# debugss_DEBUGSS_TBR_VBUSP_WRAP_TBR_CFG_TBR_CFG_00073C025000h register map
Vendor: Texas Instruments
Peripheral module from a debugger description file (folder AM275x).
Registers are 32-bit, read-only, reset 0x0 unless marked. A register's access mark holds for its fields unless they carry their own. Offsets are as the file gives them; lines under a group give offsets from that group; [hi:lo] are bit positions; {n}, {i} and the like mark numbered series; 'fields as' and 'values as' point back to an identical list; <NAME> marks a mode.

## debugss_TBR_VBUSP_WRAP_TBR_CFG_TBR_CFG
0x04 DEBUGSS_TBR_VBUSP_WRAP_TBR_CFG_TBR_CFG_CT_TBR_RAMSZ — CT-TBR RAM Size Register This register indicates the size of the local memory buffer interfaced with the CT-TBR This register can be used to determine if the CT_TBR is synthesized for System Bridge Mode only. It will read 0x00000000 in this configuration.
  [2:0] RAM_SIZE — Indicates the size of the local memory1 Read 0x0 : No local buffer. TBR Bridge only configuration Read 0x1 : 4K bytes Read 0x2 : 8K bytes Read 0x3 : 16K bytes Read 0x4 : 32K bytes Read 0x5 : 64K bytes Read 0x6 : 128K bytes Read 0x7 : Reserved
0x08 DEBUGSS_TBR_VBUSP_WRAP_TBR_CFG_TBR_CFG_FIFOSZ — CT-TBR Output FIFO Size Register This register indicates the size of output FIFO used to transfer data to the system target interface
  [2:0] FIFO_SIZE — Indicates the size of the output FIFO Read 0x0 : 128 bytes Read 0x1 : 256 bytes Read 0x2 : 512 bytes Read 0x3 : 1024 bytes Read 0x4 : 2048 bytes Read 0x5-0x7 : Reserved
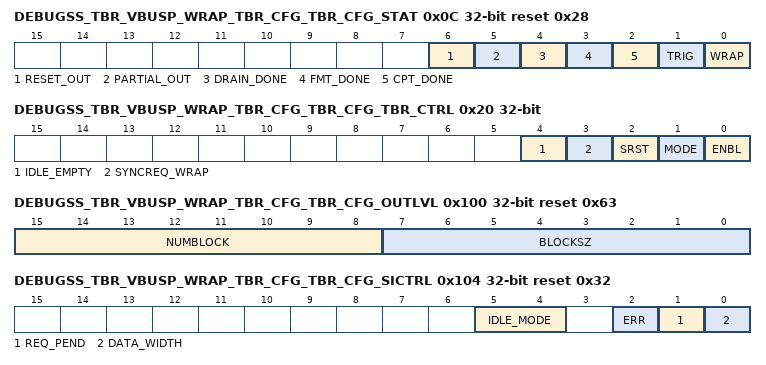
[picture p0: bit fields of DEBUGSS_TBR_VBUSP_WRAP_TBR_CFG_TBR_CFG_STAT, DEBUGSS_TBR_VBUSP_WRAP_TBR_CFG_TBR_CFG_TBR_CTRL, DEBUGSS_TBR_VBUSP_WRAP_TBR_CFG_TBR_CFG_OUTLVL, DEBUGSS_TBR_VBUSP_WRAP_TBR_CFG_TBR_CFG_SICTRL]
0x0C DEBUGSS_TBR_VBUSP_WRAP_TBR_CFG_TBR_CFG_STAT reset 0x28 — TBR Status Register This register indicates status of various functions performed by CT-TBR
  [6] RESET_OUT — Reset Active bit indicates that at least one of the domains in the CT-TBR is currently being held in reset. Read 0b : All domains and/or interfaces of the CT-TBR are out of reset Read 1b : At least one of the domains and/or interfaces of the CT-TBR are being held in reset
  [5] PARTIAL_OUT — Indicates that a partial output block (0 < Level < Trigger Threshold) is in the TBR memory (output buffer and possibly local RAM) and that an OUTFLUSH sequence may be required since there is no valid data to available to increase the amount of data past the OUTLVL threshold (i.e. local RAM buffer is empty). This bit is not set if the partial output block is the result of currently active block read request (i.e. it is already actively draining). This bit is only valid in System Bridge Mode. Read 0b : A partial frame does not exist or there is pending data in the local data RAMs that might complete any partial output blocks. Read 1b : A partial output block is in the buffer and there is not valid data available to push this through the system without an OUTFLUSH. Enabling acquisition (CTRL : ENBL 0- > 1) resets the output FIFO pointers and RAM pointers, so this bit will be set to 0 each time acquisition is enabled.
  [4] DRAIN_DONE — Indicates the whether there is data in the output FIFO. This bit is only valid in System Bridge Mode. Read 0b : There is still valid data in the CT-TBR output FIFO Read 1b : All valid data in the CT-TBR output FIFO has been transferred via the system interface. Enabling acquisition (CTRL : ENBL 0- > 1) resets the output FIFO pointers, so this bit will be set to 0 each time acquisition is enabled.
  [3] FMT_DONE — Indicates that all pending local memory transactions from the formatter are complete and no more data will be posted from the formatter. Read 0b : Data may still be pending Read 1b : Final data from the formatter has been posted. This bit is reset to 0b when the CTRL : ENBL transitions from 0b to 1b.
  [2] CPT_DONE — Indicates that ATB interface is disabled and trace data capture is complete. Read 0b : Trace capture still active Read 1b : Trace capture complete This bit is reset to 0b when the CTRL : ENBL transitions from 0b to 1b.
  [1] TRIG — Indicates that the local memory buffer has been locked as the result of a trigger. This bit is only valid in Buffer Mode and will always read 0 in System Bridge mode Read 0b : No trigger seen. Read 1b : Trigger input detected and buffer locked This bit is reset to 0b when the CTRL : ENBL transitions from 0b to 1b.
  [0] WRAP — This bit is active in buffer mode only and is not present in CT-TBR configurations that only support System bridge mode Indicates that the local memory write pointer has incremented past the upper boundary of the memory reset to the lowest address (at least once). Read 0b : No wrap Read 1b : Write pointer has wrapped This bit is reset to 0b when the CTRL : ENBL transitions from 0b to 1b
0x10 DEBUGSS_TBR_VBUSP_WRAP_TBR_CFG_TBR_CFG_RAMRDAT — RAM Read Data Register This register is used to transfer data from the local memory to client This register is not present when CT-TBR is synthesized for System Bridge Mode only.
  [31:0] DATA — The 32-bit data value pointed to by the RAMRPTR register Reading returns the value at the index specified by RAMRPTR. RAMRPTR is then incremented automatically.
0x14 DEBUGSS_TBR_VBUSP_WRAP_TBR_CFG_TBR_CFG_RAMRPTR rw — RAM Read Pointer Register Indexes into the local memory for reading 32-bit values via RAMRDAT This register is not present when CT-TBR is synthesized for System Bridge Mode only.
  [21:0] PTR — This field designates the index of the 32-bit RAM location to be read via RAMRDAT. Read returns the current value of the pointer Write sets the value and initiates a read from the designated address. This field increments automatically when a value is read from RAMRDAT. This register should not be used when the data acquisition is enabled (results are undefined). The actual width of the pointer field will be determined by the buffer size1
0x18 DEBUGSS_TBR_VBUSP_WRAP_TBR_CFG_TBR_CFG_RAMWPTR rw — This field designates the index of the 32-bit RAM location to be written via RAMWDAT. Read : Returns the current value of the pointer Write : Sets the value Writes will always force the bits 1 : 0 of write_value to 0. This register should not be used when the data acquisition is enabled (results are undefined). The actual width of the pointer field will be determined by the buffer size1
  fields as DEBUGSS_TBR_VBUSP_WRAP_TBR_CFG_TBR_CFG_RAMRPTR
0x1C DEBUGSS_TBR_VBUSP_WRAP_TBR_CFG_TBR_CFG_TRGCNT rw — Trigger Count Register This register controls the amount of data written to the local memory after a trigger input is detected
  [12:0] COUNT — Controls the number of 128-bit words written to local memory after a trigger input is detected on the CTI interface. When the input trigger is active and a trigger is detected, an internal register starts counting the number of 128-bit words written to local memory. When that counter equals COUNT + 1, the memory is locked and the CAPT_DONE and the TRIG bits in the STAT register are set. - Setting COUNT to a low index will lock trace that occurred before the trigger - Setting COUNT to a high index will lock trace that occurred after the trigger - Setting COUNT to an intermediate index will lock trace that occurred around the trigger Read : Returns the current configured value of the trigger counter Write : Sets a new value. This register can be read at any time but can only be written when acquisition is disabled in CNTL. The internal count register is not visible to the application, but it is reset cleared by hardware when the CTRL'ENBL bit transitions from 0 to 1. The width of the COUNT field is actually log2(RAM size in Bytes / 16) When configured for System Bridge only, the COUNT field is fixed a 10-bits (9 : 0). This allows the CT-TBR to capture and forward up to 1024 frames of data after the trigger event.
0x20 DEBUGSS_TBR_VBUSP_WRAP_TBR_CFG_TBR_CFG_TBR_CTRL rw — CT-TBR Control Register This register controls the global enable/disable functions of the CT-TBR
  [4] IDLE_EMPTY — Controls whether the CT_TBR can enter idle with data present Read 0x0 : All internal buffers must be empty before idle requests are acknowledged Read 0x1 : CT_TBR can idle with valid data Write 0x0 : Clear idle with valid data Write 0x1 : Set idle with valid data
  [3] SYNCREQ_WRAP — Controls whether the CT-TBR will issue a pulse on SYNREQ each time the local buffer write pointer wraps back to address 0. Read 0x0 : SYNCREQ generation is suppressed Read 0x1 : SYNCREQ on buffer wrap is enabled Write 0x0 : Disable SYNCREQ generation Write 0x1 : Enable SYNCREQ generation
  [2] SRST — Software initiated reset control Read 0x0 : Always Write 0x0 : No action Write 0x1 : Initiates a software reset
  [1] MODE — This field is the top-level control for determining the operating mode of the module Read 0x0 : Module is in Buffer Mode Read 0x1 : Module is in System Bridge Mode Write 0x0 : Set Buffer Mode Write 0x1 : Set System Bridge Mode This bit can only be written when the ENBL bit is '0' Setting it when acquisition in enabled may result in undefined behavior. This bit is read only and set to '1' when CT-TBR is synthesized for System Bridge only operation.
  [0] ENBL — This field is the top-level control for enabling trace acquisition and processing in the module. Read 0x0 : Module is disabled Read 0x1 : Module is enabled (trace data is being captured and stored to local memory) Write 0x0 : Disable module Write 0x1 : Enable module
0x24 DEBUGSS_TBR_VBUSP_WRAP_TBR_CFG_TBR_CFG_RAMWDAT rw — RAM Write Data Register This register is used to transfer data from the client to local memory This register is not present when CT-TBR is synthesized for System Bridge Mode only.
  [31:0] DATA — The 32-bit data value to be written to local memory Writing initiates the transfer of data to the location pointed at by RAMWPTR. RAMWPTR is then incremented automatically. This register should not be used when the data acquisition is enabled (results are undefined).
0x100 DEBUGSS_TBR_VBUSP_WRAP_TBR_CFG_TBR_CFG_OUTLVL rw reset 0x63 — Output FIFO Trigger Level Register This register controls the size of the data blocks transferred through the output FIFO and across the system interface
  [15:8] NUMBLOCK — Determines blocks (value + 1) that must be sent over the system interface to complete a higher level data frame for transport. This field is used to calculate the total output trigger threshold when used in conjunction with BLOCKSZ field. Output Trigger Threshold (in frames) = (BLOCKSZ + 1) * (NUMBLOCK + 1) The threshold calculations include data in the output FIFO and local RAM buffers (if local RAM exists). Read : Returns the current configured value of the number of blocks in the high level data frame Write : Sets a new value. This register is only valid when the CT-TBR is operating in System Bridge mode This register can be read at any time but can only be written when acquisition is disabled in CNTL. In addition, SW should only update NUMBLOCK when the following conditions are all true : " An output flush sequence is not active (OPCTL : OUTFLUSH == 0) " The system interface output buffer is empty (STAT : DRAIN_DONE == 1)
  [7:0] BLOCKSZ — Determines the block size (the number of 128-bit frames + 1) used by the DMA engine Reading data over the system interface. This field is used to calculate the total output trigger threshold when used in conjunction with NUMBLOCK field. The block size is used by the DMA event logic to determine when to deassert the DMA request. Output Trigger Threshold (in frames) = (BLOCKSZ + 1) * (NUMBLOCK + 1) The threshold calculations include data in the output FIFO and local RAM buffers (if local RAM exists). Read : Returns the current configured value of the block size Write : Sets a new value. The minimum value for BLOCKSZ is 0xF. If configured for less than 0xF, the behavior of the system interface is undefined. This register is only valid when the CT-TBR is operating in System Bridge mode This register can be read at any time but can only be written when acquisition is disabled in CNTL. In addition, SW should only update BLOCKSZ when the following conditions are all true : " An output flush sequence is not active (OPCTL : OUTFLUSH == 0) " The system interface output buffer is empty (STAT : DRAIN_DONE == 1)
0x104 DEBUGSS_TBR_VBUSP_WRAP_TBR_CFG_TBR_CFG_SICTRL access per field reset 0x32 — CT-TBR System Interface Control This register provides control and status for the system interface of the CT-TBR
  [5:4] IDLE_MODE rw — This bit-field controls the idle behavior of the CT-TRB Read : Indicates the Idle modes outlined below Write 00b : Set Force-Idle. For CT-TBR, Force-Idle is identical to Smart-Idle Write 01b : Set No-Idle : The CT_TBR will acknowledge the idle request, but never transition to the idle state Write 10b : Set Smart-Idle : The CT-TBR uses the smart idle protocol. This is the default mode. Write 11b : Set Smart-Idle-Wkup : Since the CT-TBR does not support internal wakeup, this mode is identical to Smart-Idle
  [2] ERR rw — This bit indicates that an access on the System Target I/F resulted in a error Read 0x0 : No errors since last clear Read 0x1 : At least one error condition on the I/F since last clear Write 0x0 : No effect Write 0x1 : Clears bit to 0 This bit clears to 0 when data acquisition is enabled (CTRL : ENBL 0- > 1)
  [1] REQ_PEND ro — This bit indicates if a read request is pending or active on the system interface Read 0x0 : No read requests pending or active Read 0x1 : A system initiator has posted a read request on the system interface and this request is pending or being serviced
  [0] DATA_WIDTH rw — This bit controls the supported access size for the system interface Read 0x0 : System interface will only support 32-bit reads Read 0x1 : System interface will only support 64-bit reads Write 0x0 : Set 32-bit mode Write 0x1 : Set 64-bit mode This bit is RO and set to 0 when synthesized for 32-bit data width
0x108 DEBUGSS_TBR_VBUSP_WRAP_TBR_CFG_TBR_CFG_IDPERIOD rw — ID Repeat Period Register This register controls the number of frames (without and ID change marker) that will be sent before the formatter forces and ID marker
  [9:0] PERIOD — Controls the number of 128-bit frames (with no ID change markers) that the formatter will forward before forcing an artificial ID change. Read : Returns the current configured value of the period Write : Sets the value Setting to 0 disables the forcing of IDs, but this is not recommended. PERIOD should only be updated when trace acquisition is disabled
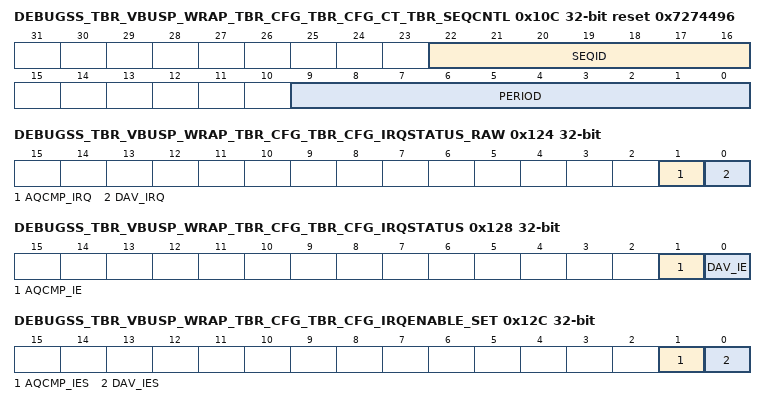
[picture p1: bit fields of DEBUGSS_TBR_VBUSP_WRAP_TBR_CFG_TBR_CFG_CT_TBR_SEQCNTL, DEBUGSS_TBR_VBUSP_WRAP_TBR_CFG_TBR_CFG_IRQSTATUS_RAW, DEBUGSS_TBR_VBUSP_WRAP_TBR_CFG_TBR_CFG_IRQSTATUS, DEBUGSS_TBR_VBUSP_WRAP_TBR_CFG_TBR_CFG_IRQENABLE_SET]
0x10C DEBUGSS_TBR_VBUSP_WRAP_TBR_CFG_TBR_CFG_CT_TBR_SEQCNTL rw reset 0x7274496
  [22:16] SEQID — PERIOD1This defined the ATID used when inserting the incrementing sequence byte. The reset value is the highest free ID supported in the TWP specification, but this can be overwritten by SW if there are system collisions
  [9:0] PERIOD — Controls the number of 128-bit frames that the formatter will forward before inserting an 8-bit incrementing sequence number into a frame using ATID defined in SEQID Read : Returns the current configured value of the period Write : Sets the value Setting to 0 disables the insertion of the incrementing sequence bytes, PERIOD should only be updated when trace acquisition is disabled
0x120 DEBUGSS_TBR_VBUSP_WRAP_TBR_CFG_TBR_CFG_EOI rw — CT-TBR EOI register This register is the End of Interrupt used by SW to signal HW that an interrupt service is complete and an interrupt can be rearmed.
  [0] EOI_VECT — This bit is used by SW to signal that a particular interrupt generated by the IP can be rearmed. Read 0x0 : Always Write 0x0 : DAV_IRQ is rearmed (it is IRQ index 0 for this IP) Write 0x1 : AQCMP_IRQ is rearmed (it is IRQ index 1)
0x124 DEBUGSS_TBR_VBUSP_WRAP_TBR_CFG_TBR_CFG_IRQSTATUS_RAW rw — CT-TBR IRQ Status (Raw) register This register provides control and status for the interrupt/event interface The IRQSTATUS_RAW register may be modified while acquisition is enabled
  [1] AQCMP_IRQ — This bit controls the acquisition complete interrupt/event generation for testing Read 0x0 : Acquisition complete interrupt is not active Read 0x1 : Acquisition complete interrupt is active and awaiting completion. The enabled state is not considered. Write 0x0 : No effect Write 0x1 : Sets the interrupt request for testing
  [0] DAV_IRQ — This bit controls the data available interrupt/event generation for testing Read 0x0 : Data available interrupt is not active Read 0x1 : Data available interrupt is active and awaiting completion. The enabled state is not considered. Write 0x0 : No effect Write 0x1 : Sets the interrupt request for testing
0x128 DEBUGSS_TBR_VBUSP_WRAP_TBR_CFG_TBR_CFG_IRQSTATUS rw — CT-TBR IRQ Status register This register provides control and status for the interrupt/event interface The IRQSTATUS register may be modified while acquisition is enabled
  [1] AQCMP_IE — Acquisition complete interrupt enable Read 0x0 : Acquisition complete interrupt/event generation is either not pending or it is not enabled Read 0x1 : The acquisition complete interrupt is pending and enabled. Write 0x0 : No effect Write 0x1 : Clears a pending Acquisition complete interrupt
  [0] DAV_IE — Data Available interrupt enable Read 0x0 : Data available interrupt/event generation is either not pending or it is disabled Read 0x1 : Data available interrupt is pending and enabled. Write 0x0 : No effect Write 0x1 : Clears a pending data available interrupt
0x12C DEBUGSS_TBR_VBUSP_WRAP_TBR_CFG_TBR_CFG_IRQENABLE_SET rw — CT-TBR IRQ Enable set register This register provides control for the interrupt/event interface The IRQENABLE_SET register may be modified while acquisition is enabled
  [1] AQCMP_IES — Provides enable state and sets the enable of the acquisition complete interrupt/event Read 0x0 : The acquisition complete interrupt is disabled Read 0x1 : The acquisition complete interrupt is enabled Write 0x0 : No effect Write 0x1 : Enables the acquisition complete interrupt/event
  [0] DAV_IES — Provides enable state and sets the enable of the data available interrupt/event Read 0x0 : The data available interrupt is disabled Read 0x1 : The data available interrupt is enabled Write 0x0 : No effect Write 0x1 : Enables the data available interrupt/event
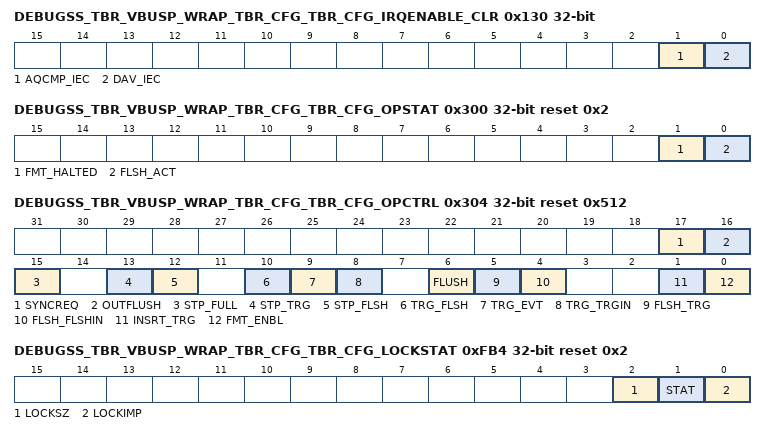
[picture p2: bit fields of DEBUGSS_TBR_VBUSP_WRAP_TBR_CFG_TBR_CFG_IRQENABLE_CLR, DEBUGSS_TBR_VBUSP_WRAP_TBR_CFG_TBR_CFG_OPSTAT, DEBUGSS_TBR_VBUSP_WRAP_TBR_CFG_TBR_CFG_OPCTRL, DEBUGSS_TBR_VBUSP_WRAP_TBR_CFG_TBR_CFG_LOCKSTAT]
0x130 DEBUGSS_TBR_VBUSP_WRAP_TBR_CFG_TBR_CFG_IRQENABLE_CLR rw — CT-TBR IRQ Enable clear register This register provides control for the interrupt/event interface The IRQENABLE_CLR register may be modified while acquisition is enabled
  [1] AQCMP_IEC — Provides enable state and clears the enable of the data available interrupt/event Read 0x0 : The acquisition complete interrupt is disabled Read 0x1 : The acquisition complete interrupt is enabled Write 0x0 : No effect Write 0x1 : Disables the acquisition complete interrupt/event
  [0] DAV_IEC — Provides enable state and clears the enable of the data available interrupt/event Read 0x0 : The data available interrupt is disabled Read 0x1 : The data available interrupt is enabled Write 0x0 : No effect Write 0x1 : Disables the data available interrupt/event
0x300 DEBUGSS_TBR_VBUSP_WRAP_TBR_CFG_TBR_CFG_OPSTAT reset 0x2 — Operation Status Register This register provides information on the status of various operations of the CT-TBR
  [1] FMT_HALTED — This bit indicates that the formatter is halted and the last available data has been written to the local memory. It is functionally equivalent to the FMT_DONE bit in the STAT register. Read 0x0 : Formatter block is active Read 0x1 : Formatter block is disabled This bit is cleared by hardware when the CTRL'ENBL bit transitions from 0 to 1.
  [0] FLSH_ACT — This bit indicates that a flush request is being processed by the CT-TBR Read 0x0 : No flush requests are active Read 0x1 : Flush request is pending completion
0x304 DEBUGSS_TBR_VBUSP_WRAP_TBR_CFG_TBR_CFG_OPCTRL access per field reset 0x512
  [17] SYNCREQ rw — This bit is allows the SW to stimulate a synchronization request to all the upstream trace components. Read 0x0 : This bit always reads as 0 Write 0x0 : Has no effect Write 0x1 : Results in the assertion of the SYNCREQ signal on the ATB target for one ATCLK cycle. SYNCREQ is available in any operating mode. SYNCREQ should only be written while trace acquisition is enabled.
  [16] OUTFLUSH rw — This bit is the flush control. For the output FIFO (System Bridge Mode) it triggers a flush of this buffer and the flush completes when the last OUTLEVEL + 1 sized burst is read on the system Interface. Read 0x0 : No output flush operation is active Read 0x1 : Output flush operation is active Write 0x0 : No meaning Write 0x1 : Initiate an output buffer flush. Automatically clears to 0 when the operation completes OUTFLUSH may be written while trace acquisition is enabled
  [15] STP_FULL rw — This bit controls whether the formatter stops operation when the local memory buffer is full. This 'one-shot' mode prevents the write pointer from wrapping, Read 0x0 : Formatter continues when write pointer wraps back to the lowest address Read 0x1 : Formatter stops operation when the local memory is full Write 0x0 : Disable formatter halt on full Write 0x1 : Enable formatter halt on full This bit is only functional when the CT-TBR is configured for Buffer Mode (CTRL : MODE == 0).
  [13] STP_TRG rw — This bit controls whether the formatter stops operation when a trigger is detected Read 0x0 : Formatter continues when trigger is detected Read 0x1 : Formatter stops operation when trigger is detected Write 0x0 : Disable formatter halt on trigger Write 0x1 : Enable formatter halt on trigger
  [12] STP_FLSH rw — This bit controls whether the formatter stops operation when a flush completes Read 0x0 : Formatter continues after flush completion Read 0x1 : Formatter stops operation when flush completes Write 0x0 : Disable formatter halt on flush completion Write 0x1 : Enable formatter halt on flush completion
  [10] TRG_FLSH rw — This bit controls whether a trigger event is generated when a flush completes Read 0x0 : No trigger event generated when flush is completed. Read 0x1 : Trigger event generated Write 0x0 : Disable trigger event generation Write 0x1 : Enable trigger event generation
  [9] TRG_EVT rw — This bit controls whether the action associated with a trigger is delayed until the trigger counter matches the value in TRGCNT : COUNT + 1. Read 0x0 : No trigger counter delay Read 0x1 : Trigger action delayed until trigger count match Write 0x0 : Disable trigger delay Write 0x1 : Enable trigger delay
  [8] TRG_TRGIN rw — This bit controls whether a trigger event is generated when a rising edge is detected on the TRIGIN input on the CTI interface. Setting this bit also enables trigger event generation when a trigger ID (ATID = 0x7d) is seen on the ATB interface. Read 0x0 : No trigger event generated on TRIGIN assertion. Read 0x1 : Trigger event generated Write 0x0 : Disable trigger event generation Write 0x1 : Enable trigger event generation
  [6] FLUSH rw — This bit is the manual flush control. It triggers a flush from the trace data sources into the CT-TBR Read 0x0 : No manual flush operation is active Read 0x1 : Manual flush operation is active Write 0x0 : No meaning Write 0x1 : Initiate a manual flush. Automatically clears to 0 when the operation completes FLUSH may be written while trace acquisition is enabled
  [5] FLSH_TRG rw — This bit controls whether a flush operation is initiated when a trigger condition is detected by the CT-TBR Read 0x0 : Flush on trigger event is disabled Read 0x1 : Flush on trigger event is enabled Write 0x0 : Disable flush on trigger event Write 0x1 : Enable flush on trigger event
  [4] FLSH_FLSHIN rw — This bit controls whether a flush operation is initiated when a rising edge is detected on the FLUSHIN input signal Read 0x0 : Flush on FLUSHIN is disabled Read 0x1 : Flush on FLUSHIN is enabled Write 0x0 : Disable flush on FLUSHIN Write 0x1 : Enable flush on FLUSHIN
  [1] INSRT_TRG rw — This bit controls whether the TWP trigger sequence is inserted into the TWP frame a trigger condition is encountered Read 0x0 : Trigger insertion is disabled Read 0x1 : Trigger insertion is enabled Write 0x0 : Disable trigger insertion Write 0x1 : Enable trigger insertion
  [0] FMT_ENBL rw — This bit controls whether the ATB input data is formatted into 128-bit TWP frames Read 0x0 : Formatting is disabled Read 0x1 : Formatting is enabled Write 0x0 : Disable formatting Write 0x1 : Enable formatting
0xFA0 DEBUGSS_TBR_VBUSP_WRAP_TBR_CFG_TBR_CFG_CLAIMSET access per field reset 0x1 — The Claim Tag Set Register The register is used to manage handshakes between application and tools SW using the CT-TBR
  [3:0] CTSET rw — This bit sets the Claim Tag Read 0xF : Always. Indicates that claim tag has 4 valid bits Write 0x0 : No effect Write 0x1-F : Bit value of '1' sets the corresponding Claim Tag bit
0xFA4 DEBUGSS_TBR_VBUSP_WRAP_TBR_CFG_TBR_CFG_CLAIMCLR — The Claim Tag Clear Register The register is used to manage handshakes between application and tools SW using the CT-TBR
  [3:0] CTCLR — This bit clears the Claim Tag Read : The current claim tag value Write 0x0 : No effect Write 0x1-F : Bit value of '1' clears the corresponding bit in the Claim Tag
0xFB0 DEBUGSS_TBR_VBUSP_WRAP_TBR_CFG_TBR_CFG_LOCKACC — The Lock Access Register The register is used to enabled application use of the CT-TBR
  [31:0] CODE — This bit-field is used to unlock the CT-TBR for use by the application Write 0xC5ACCE55 : Unlocks the CT-TBR Write any other value : Lock the CT-TBR
0xFB4 DEBUGSS_TBR_VBUSP_WRAP_TBR_CFG_TBR_CFG_LOCKSTAT reset 0x2 — The Lock Status Register The register is used to manage application use of the CT-TBR
  [2] LOCKSZ — This bit-field indicates the size of the lock access bit-field Read 0x0 : indicates the lock access field is 32-bits wide
  [1] STAT — This bit-field indicates the current state of the lock Read 0x0 : indicates the module is not locked from application accesses Read 0x1 : Indicates the module is locked
  [0] LOCKIMP — This bit-field indicates if the module implements a lock access mechanism Read 0x1 : Indicates a lock is present
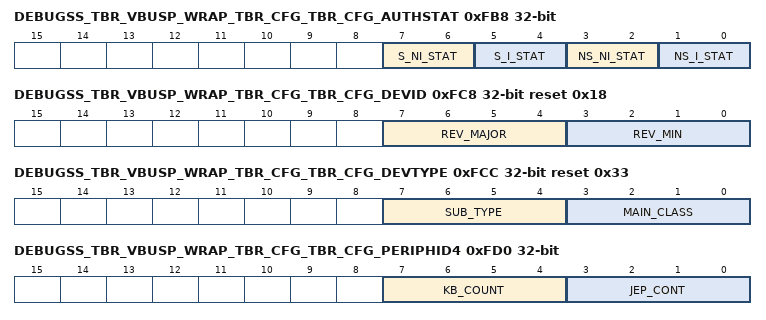
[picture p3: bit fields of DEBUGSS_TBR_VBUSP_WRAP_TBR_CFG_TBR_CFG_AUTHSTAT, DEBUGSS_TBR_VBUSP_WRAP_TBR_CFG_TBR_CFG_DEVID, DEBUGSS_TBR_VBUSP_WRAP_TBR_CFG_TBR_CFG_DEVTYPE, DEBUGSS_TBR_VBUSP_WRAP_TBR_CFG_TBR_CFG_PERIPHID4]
0xFB8 DEBUGSS_TBR_VBUSP_WRAP_TBR_CFG_TBR_CFG_AUTHSTAT — Authorization Status Register Indicates which security features (if any) are implemented in the module.
  [7:6] S_NI_STAT — Secure, non-invasive debug status Read 0x0 : Indicates CT-TBR does not implement this feature
  [5:4] S_I_STAT
  [3:2] NS_NI_STAT
  [1:0] NS_I_STAT — Non-secure, invasive debug status Read 0x0 : Indicates CT-TBR does not implement this feature
0xFC8 DEBUGSS_TBR_VBUSP_WRAP_TBR_CFG_TBR_CFG_DEVID reset 0x18 — Device Identification Register Defines the major and minor versions of this implementation of the CT-TBR
  [7:4] REV_MAJOR
  [3:0] REV_MIN — Minor revision number Read 0x0 : The only minor revision currently supported
0xFCC DEBUGSS_TBR_VBUSP_WRAP_TBR_CFG_TBR_CFG_DEVTYPE reset 0x33 — Device Type Register Indicates the top-level function of the module
  [7:4] SUB_TYPE — Identifies the sub-type based upon class Read 0x2 : Indicates the CT-TBR is an embedded trace buffer
  [3:0] MAIN_CLASS — Identifies the top level class to the module Read 0x1 : Indicates the CT-TBR is a trace sink
0xFD0 DEBUGSS_TBR_VBUSP_WRAP_TBR_CFG_TBR_CFG_PERIPHID4 — Peripheral Identification Register Number 4 The Peripheral ID registers indicate module specifics like manufacturer and part number
  [7:4] KB_COUNT — Indicates the number of 4KB block of configuration memory (+ 1) used by this module. Read 0x0 : CT-TBR uses one block
  [3:0] JEP_CONT — JEDEC manufacture code continuation code Read 0x0 : TI JEP number does not use continuation
0xFD4 DEBUGSS_TBR_VBUSP_WRAP_TBR_CFG_TBR_CFG_PERIPHID5 — Peripheral Identification Register Number 5 The Peripheral ID registers indicate module specifics like manufacturer and part number
  [7:0] PID5 — Read 0x0 : As per CoreSight Architecture Specification
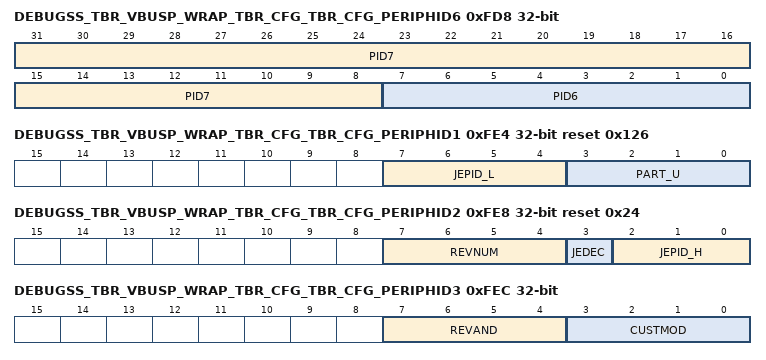
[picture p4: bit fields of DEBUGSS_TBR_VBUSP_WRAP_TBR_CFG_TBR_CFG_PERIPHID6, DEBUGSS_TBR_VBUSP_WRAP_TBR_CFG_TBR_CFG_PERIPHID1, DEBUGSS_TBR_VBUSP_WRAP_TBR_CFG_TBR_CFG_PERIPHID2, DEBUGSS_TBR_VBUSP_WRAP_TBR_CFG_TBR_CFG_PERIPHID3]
0xFD8 DEBUGSS_TBR_VBUSP_WRAP_TBR_CFG_TBR_CFG_PERIPHID6 — Peripheral Identification Register Number 6 The Peripheral ID registers indicate module specifics like manufacturer and part number
  [31:8] PID7
  [7:0] PID6 — Read 0x0 : As per CoreSight Architecture Specification
0xFDC DEBUGSS_TBR_VBUSP_WRAP_TBR_CFG_TBR_CFG_PERIPHID7 — Peripheral Identification Register Number 7 The Peripheral ID registers indicate module specifics like manufacturer and part number
  [7:0] PID7 — Read 0x0 : As per CoreSight Architecture Specification
0xFE0 DEBUGSS_TBR_VBUSP_WRAP_TBR_CFG_TBR_CFG_PERIPHID0 reset 0x223 — Peripheral Identification Register Number 0 The Peripheral ID registers indicate module specifics like manufacturer and part number
  [7:0] PART_ML — The middle and lower BCD value of the part number. Read 0xDF : CT-TBR BCD part number is EDF
0xFE4 DEBUGSS_TBR_VBUSP_WRAP_TBR_CFG_TBR_CFG_PERIPHID1 reset 0x126 — Peripheral Identification Register Number 1 The Peripheral ID registers indicate module specifics like manufacturer and part number
  [7:4] JEPID_L — JEP106 ID[3 : 0]. Read 0x7 : TI JEP106 ID is 0x17
  [3:0] PART_U — The upper BCD value of the part number. Read 0xE : CT-TBR BCD part number is EDF
0xFE8 DEBUGSS_TBR_VBUSP_WRAP_TBR_CFG_TBR_CFG_PERIPHID2 reset 0x24 — Peripheral Identification Register Number 2 The Peripheral ID registers indicate module specifics like manufacturer and part number
  [7:4] REVNUM — Revision number of the peripheral module Read 0x0 : Only revision of CT-TBR
  [3] JEDEC — Indicates JEDEC ID was used Read 0x1 : JEDEC ID is used
  [2:0] JEPID_H — JEP106 ID[6 : 4]. Read 0x1 : TI JEP106 ID is 0x17
0xFEC DEBUGSS_TBR_VBUSP_WRAP_TBR_CFG_TBR_CFG_PERIPHID3 — Peripheral Identification Register Number 3 The Peripheral ID registers indicate module specifics like manufacturer and part number
  [7:4] REVAND — Indicates the errata fix version of the IP Read 0x0 : CT-TBR uses one block
  [3:0] CUSTMOD — Indicates that the module was reusable IP that was modified by the customer Read 0x0 : CT-TBR is native IP
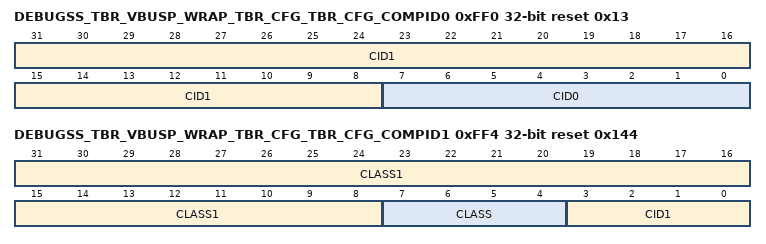
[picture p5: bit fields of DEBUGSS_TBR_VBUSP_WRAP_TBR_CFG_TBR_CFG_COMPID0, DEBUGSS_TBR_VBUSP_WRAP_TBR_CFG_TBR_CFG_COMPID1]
0xFF0 DEBUGSS_TBR_VBUSP_WRAP_TBR_CFG_TBR_CFG_COMPID0 reset 0x13 — Component Identification Register Number 0 The Component ID registers places a known bit pattern in memory that indicates that a 4K configuration block is valid and supports a peripheral
  [31:8] CID1
  [7:0] CID0 — The fixed preamble for the component ID Read 0x0D : CID0 Preamble is fixed at 0x0D
0xFF4 DEBUGSS_TBR_VBUSP_WRAP_TBR_CFG_TBR_CFG_COMPID1 reset 0x144 — Component Identification Register Number 1 The Component ID registers places a known bit pattern in memory that indicates that a 4K configuration block is valid and supports a peripheral
  [31:8] CLASS1
  [7:4] CLASS — Indicates the class of the component Read 0x9 : CT-TBR is a CoreSight component
  [3:0] CID1 — The fixed preamble for the component ID Read 0x0 : CID1 Preamble is fixed at 0x0
0xFF8 DEBUGSS_TBR_VBUSP_WRAP_TBR_CFG_TBR_CFG_COMPID2 reset 0x5 — Component Identification Register Number 2 The Component ID registers places a known bit pattern in memory that indicates that a 4K configuration block is valid and supports a peripheral
  [7:0] CID2 — The fixed preamble for the component ID Read 0x05 : CID2 Preamble is fixed at 0x05
0xFFC DEBUGSS_TBR_VBUSP_WRAP_TBR_CFG_TBR_CFG_COMPID3 reset 0x177 — 2Component Identification Register Number 3 The Component ID registers places a known bit pattern in memory that indicates that a 4K configuration block is valid and supports a peripheral
  [7:0] CID3 — The fixed preamble for the component ID Read 0x05 : CID2 Preamble is fixed at 0x05
